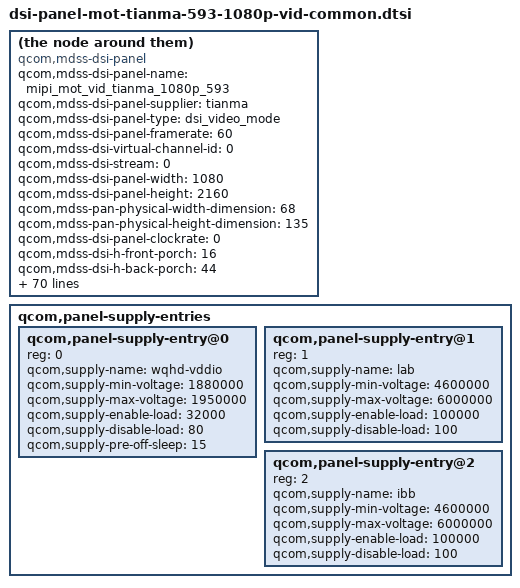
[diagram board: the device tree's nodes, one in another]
/* Copyright (c) 2017, The Linux Foundation. All rights reserved.
 *
 * This program is free software; you can redistribute it and/or modify
 * it under the terms of the GNU General Public License version 2 and
 * only version 2 as published by the Free Software Foundation.
 *
 * This program is distributed in the hope that it will be useful,
 * but WITHOUT ANY WARRANTY; without even the implied warranty of
 * MERCHANTABILITY or FITNESS FOR A PARTICULAR PURPOSE.  See the
 * GNU General Public License for more details.
 */

compatible = "qcom,mdss-dsi-panel";
qcom,mdss-dsi-panel-name = "mipi_mot_vid_tianma_1080p_593";
qcom,mdss-dsi-panel-supplier = "tianma";
qcom,mdss-dsi-panel-type = "dsi_video_mode";
qcom,mdss-dsi-panel-framerate = <60>;
qcom,mdss-dsi-virtual-channel-id = <0>;
qcom,mdss-dsi-stream = <0>;
qcom,mdss-dsi-panel-width = <1080>;
qcom,mdss-dsi-panel-height = <2160>;
qcom,mdss-pan-physical-width-dimension = <68>;
qcom,mdss-pan-physical-height-dimension = <135>;

qcom,mdss-dsi-panel-clockrate = <0>;
qcom,mdss-dsi-h-front-porch = <16>;
qcom,mdss-dsi-h-back-porch = <44>;
qcom,mdss-dsi-h-pulse-width = <12>;
qcom,mdss-dsi-h-sync-skew = <0>;
qcom,mdss-dsi-v-back-porch = <8>;
qcom,mdss-dsi-v-front-porch = <14>;
qcom,mdss-dsi-v-pulse-width = <4>;
qcom,mdss-dsi-h-left-border = <0>;
qcom,mdss-dsi-h-right-border = <0>;
qcom,mdss-dsi-v-top-border = <0>;
qcom,mdss-dsi-v-bottom-border = <0>;
qcom,mdss-dsi-bpp = <24>;
qcom,mdss-dsi-underflow-color = <0xff>;
qcom,mdss-dsi-border-color = <0>;
qcom,mdss-dsi-on-command = [
	39 00 00 00 00 00 04 B9 FF 83 99
	39 00 00 00 00 00 03 51 0C CC
	15 00 00 00 00 00 02 53 2C
	15 01 00 00 05 00 02 55 01
	39 00 00 00 00 00 0A CA 23 23 23 23 23 23 22 20 20
	05 01 00 00 78 00 01 11
	39 00 00 00 00 00 09 C9 03 00 14 1E 93 1E 00 91
	39 01 00 00 01 00 2D B4 00 FF 00 14 04 A9 00 00 0C
		00 00 02 00 28 05 0B 0D 21 03 01 00 01 B2 87 00 14
		04 A9 00 00 0C 00 00 02 00 28 05 0B 0D 01 00 01 B2 01
	05 01 00 00 01 00 01 29];	/* display on */
qcom,mdss-dsi-off-command = [
	39 00 00 00 00 00 04 B9 FF 83 99
	15 00 00 00 00 00 02 B1 00
	05 00 00 00 00 00 01 28		/* display_off */
	05 01 00 00 3C 00 01 10	/* enter sleep mode */
	05 01 00 00 00 00 01 4F];


qcom,mdss-dsi-on-command-state = "dsi_lp_mode";
qcom,mdss-dsi-off-command-state = "dsi_lp_mode";

qcom,mdss-dsi-cabc-ui-command = [15 01 00 00 00 00 02 55 01];
qcom,mdss-dsi-cabc-ui-command-state = "dsi_hs_mode";
qcom,mdss-dsi-cabc-mv-command = [15 01 00 00 00 00 02 55 03];
qcom,mdss-dsi-cabc-mv-command-state = "dsi_hs_mode";
qcom,mdss-dsi-cabc-dis-command = [15 01 00 00 00 00 02 55 00];
qcom,mdss-dsi-cabc-dis-command-state = "dsi_hs_mode";
qcom,mdss-dsi-hbm-on-command = [39 01 00 00 00 00 03 51 0F FF];
qcom,mdss-dsi-hbm-on-command-state = "dsi_hs_mode";
qcom,mdss-dsi-hbm-off-command = [39 01 00 00 00 00 03 51 0C CC];
qcom,mdss-dsi-hbm-off-command-state = "dsi_hs_mode";
qcom,mdss-dsi-hbm-type = "lcd-dcs-wled";

qcom,mdss-dsi-h-sync-pulse = <0>;
qcom,mdss-dsi-traffic-mode = "burst_mode";
qcom,mdss-dsi-bllp-eof-power-mode;
qcom,mdss-dsi-bllp-power-mode;
qcom,mdss-dsi-lane-0-state;
qcom,mdss-dsi-lane-1-state;
qcom,mdss-dsi-lane-2-state;
qcom,mdss-dsi-lane-3-state;
qcom,mdss-dsi-panel-timings-phy-v2 = [
	24 1F 08 09 05 03 04 A0
	24 1F 08 09 05 03 04 A0
	24 1F 08 09 05 03 04 A0
	24 1F 08 09 05 03 04 A0
	24 1B 08 09 05 03 04 A0];
qcom,mdss-dsi-t-clk-post = <0x0D>;
qcom,mdss-dsi-t-clk-pre = <0x30>;
qcom,mdss-dsi-bl-min-level = <1>;
qcom,mdss-dsi-bl-max-level = <4095>;
qcom,mdss-dsi-dma-trigger = "trigger_sw";
qcom,mdss-dsi-mdp-trigger = "none";
qcom,mdss-dsi-bl-pmic-control-type = "bl_ctrl_wled";
qcom,mdss-dsi-reset-sequence = <1 10>, <0 5>, <1 35>;
qcom,mdss-dsi-lp11-init;
qcom,mdss-dsi-tx-eot-append;

qcom,esd-check-enabled;
qcom,mdss-dsi-panel-status-check-mode = "reg_read";
qcom,mdss-dsi-panel-status-read-length = <1>;
qcom,mdss-dsi-panel-status-command = [06 01 00 01 00 00 01 0A];
qcom,mdss-dsi-panel-status-command-state = "dsi_hs_mode";
qcom,mdss-dsi-panel-status-value = <0x9d>;
qcom,mdss-dsi-panel-reply-long-response;

qcom,panel-supply-entries {
	#address-cells = <1>;
	#size-cells = <0>;

	qcom,panel-supply-entry@0 {
		reg = <0>;
		qcom,supply-name = "wqhd-vddio";
		qcom,supply-min-voltage = <1880000>;
		qcom,supply-max-voltage = <1950000>;
		qcom,supply-enable-load = <32000>;
		qcom,supply-disable-load = <80>;
		qcom,supply-pre-off-sleep = <15>;
	};

	qcom,panel-supply-entry@1 {
		reg = <1>;
		qcom,supply-name = "lab";
		qcom,supply-min-voltage = <4600000>;
		qcom,supply-max-voltage = <6000000>;
		qcom,supply-enable-load = <100000>;
		qcom,supply-disable-load = <100>;
	};

	qcom,panel-supply-entry@2 {
		reg = <2>;
		qcom,supply-name = "ibb";
		qcom,supply-min-voltage = <4600000>;
		qcom,supply-max-voltage = <6000000>;
		qcom,supply-enable-load = <100000>;
		qcom,supply-disable-load = <100>;
	};
};
